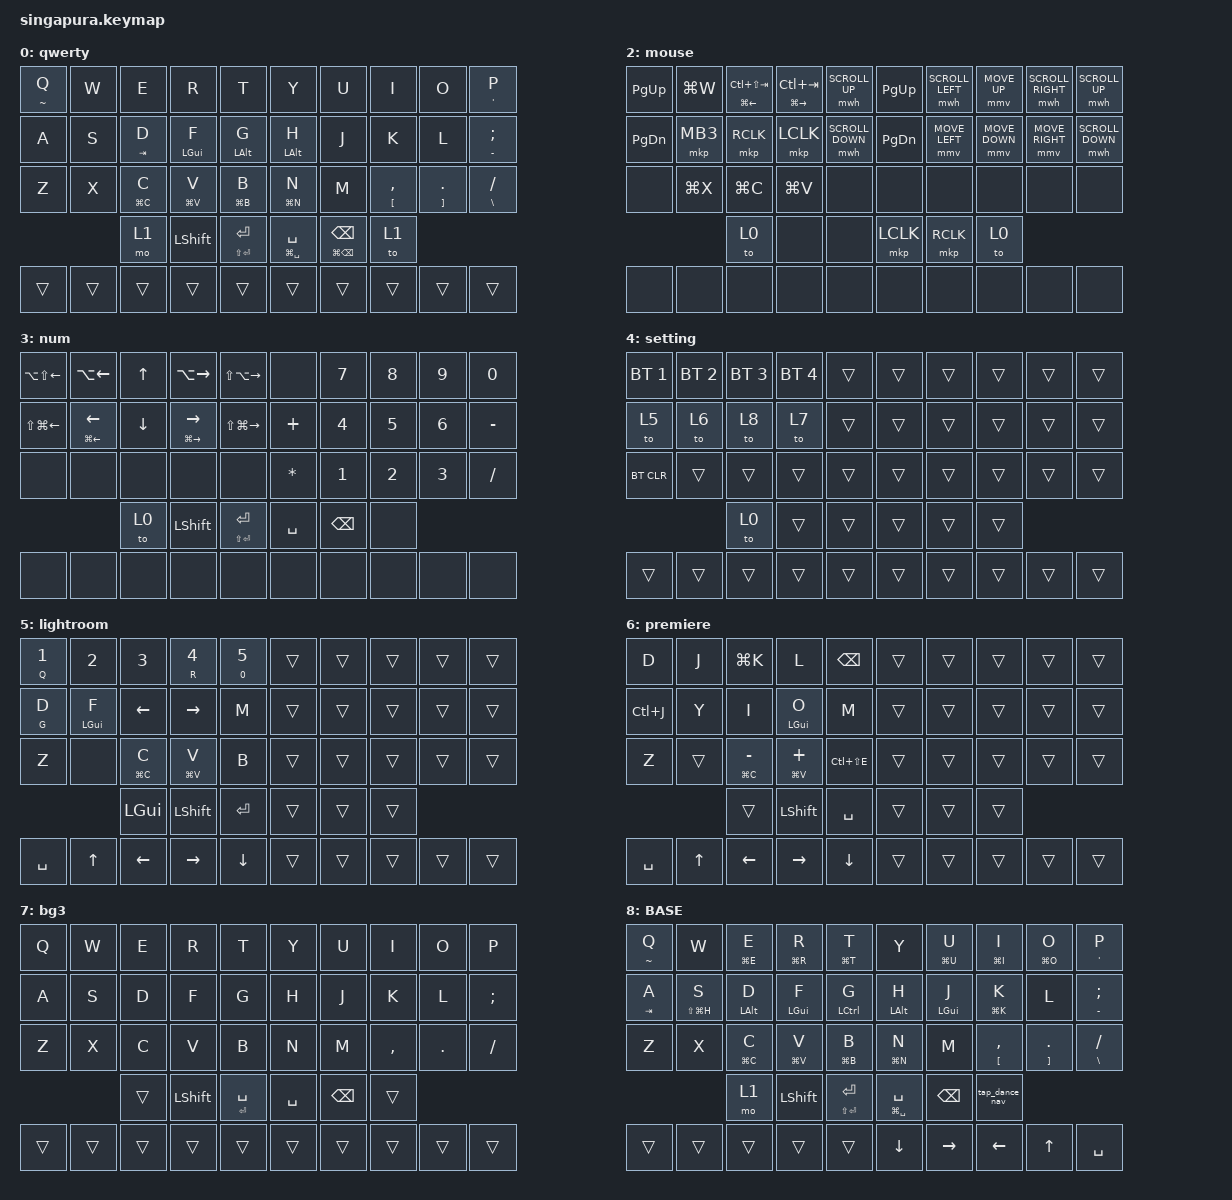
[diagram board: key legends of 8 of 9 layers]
// Copyright 2023 saikocat (@saikocat)
// SPDX-License-Identifier: MIT

#include <behaviors.dtsi>
#include <dt-bindings/zmk/bt.h>
#include <dt-bindings/zmk/keys.h>
#include <dt-bindings/zmk/mouse.h>

#define U_MOUSE_MOVE_MAX 1400

#undef MOVE_UP
#undef MOVE_DOWN
#undef MOVE_LEFT
#undef MOVE_RIGHT

#define MOVE_UP MOVE_VERT(-U_MOUSE_MOVE_MAX)
#define MOVE_DOWN MOVE_VERT(U_MOUSE_MOVE_MAX)
#define MOVE_LEFT MOVE_HOR(-U_MOUSE_MOVE_MAX)
#define MOVE_RIGHT MOVE_HOR(U_MOUSE_MOVE_MAX)
#define U_MOUSE_SCROLL_MAX 12

#undef SCROLL_UP
#undef SCROLL_DOWN
#undef SCROLL_LEFT
#undef SCROLL_RIGHT

#define SCROLL_UP SCROLL_VERT(U_MOUSE_SCROLL_MAX)
#define SCROLL_DOWN SCROLL_VERT(-U_MOUSE_SCROLL_MAX)
#define SCROLL_LEFT SCROLL_HOR(-U_MOUSE_SCROLL_MAX)
#define SCROLL_RIGHT SCROLL_HOR(U_MOUSE_SCROLL_MAX)

&mmv {
    time-to-max-speed-ms = <250>;
    acceleration-exponent = <1>;
};

&mwh {
    time-to-max-speed-ms = <250>;
    acceleration-exponent = <1>;
};

/ {
    combos {
        compatible = "zmk,combos";

        combo_esc {
            timeout-ms = <25>;
            key-positions = <0 1>;
            bindings = <&kp ESC>;
        };

        combo_settings {
            timeout-ms = <25>;
            bindings = <&to 4>;
            key-positions = <31 32 24>;
        };

        combo_pp {
            timeout-ms = <25>;
            bindings = <&kp C_PP>;
            key-positions = <4 5>;
        };

        combo_LEFT_PARENTHESIS {
            timeout-ms = <25>;
            bindings = <&kp LEFT_PARENTHESIS>;
            key-positions = <6 7>;
        };

        combo_RIGHT_PARENTHESIS {
            timeout-ms = <25>;
            bindings = <&kp RIGHT_PARENTHESIS>;
            key-positions = <7 8>;
        };

        combo_VOLUME_UP {
            timeout-ms = <25>;
            bindings = <&kp C_VOLUME_UP>;
            key-positions = <22 23>;
        };

        combo_VOLUME_DOWN {
            timeout-ms = <25>;
            bindings = <&kp C_VOLUME_DOWN>;
            key-positions = <21 20>;
        };

        combo_MUTE {
            timeout-ms = <25>;
            bindings = <&kp C_MUTE>;
            key-positions = <21 22>;
        };

        combo_plus {
            timeout-ms = <25>;
            bindings = <&kp KP_PLUS>;
            key-positions = <19 29>;
        };

        combo_multiply {
            timeout-ms = <25>;
            bindings = <&kp ASTERISK>;
            key-positions = <28 19>;
        };

        combo_equal {
            timeout-ms = <25>;
            bindings = <&kp EQUAL>;
            key-positions = <28 29>;
        };

        combo_no1 {
            timeout-ms = <35>;
            bindings = <&kp N1>;
            key-positions = <34 26>;
        };

        combo_no2 {
            timeout-ms = <35>;
            bindings = <&kp N2>;
            key-positions = <34 27>;
        };

        combo_no3 {
            timeout-ms = <35>;
            bindings = <&kp N3>;
            key-positions = <34 28>;
        };

        combo_no4 {
            timeout-ms = <35>;
            bindings = <&kp N4>;
            key-positions = <34 16>;
        };

        combo_no5 {
            timeout-ms = <35>;
            bindings = <&kp N5>;
            key-positions = <34 17>;
        };

        combo_no6 {
            timeout-ms = <35>;
            bindings = <&kp N6>;
            key-positions = <34 18>;
        };

        combo_no7 {
            timeout-ms = <35>;
            bindings = <&kp N7>;
            key-positions = <34 6>;
        };

        combo_no8 {
            timeout-ms = <35>;
            bindings = <&kp N8>;
            key-positions = <34 7>;
        };

        combo_no9 {
            timeout-ms = <35>;
            bindings = <&kp N9>;
            key-positions = <34 8>;
        };

        combo_no0 {
            timeout-ms = <35>;
            bindings = <&kp N0>;
            key-positions = <9 34>;
        };

        combo_leftscreen {
            timeout-ms = <25>;
            bindings = <&kp F7>;
            key-positions = <0 10>;
        };

        combo_rightscreen {
            timeout-ms = <25>;
            bindings = <&kp F9>;
            key-positions = <4 14>;
        };

        combo_nexttrack {
            timeout-ms = <25>;
            bindings = <&kp C_NEXT>;
            key-positions = <21 22 23>;
        };

        combo_prevtrack {
            timeout-ms = <25>;
            bindings = <&kp C_PREV>;
            key-positions = <20 21 22>;
        };

        combo_changelang {
            timeout-ms = <35>;
            bindings = <&kp LC(SPACE)>;
            key-positions = <14 13 15 16>;
        };

        combo_spaces {
            timeout-ms = <30>;
            bindings = <&kp F8>;
            key-positions = <1 3>;
        };

        combo_to0 {
            timeout-ms = <15>;
            bindings = <&to 0>;
            key-positions = <31 32>;
        };

        combo_screenshot {
            timeout-ms = <35>;
            bindings = <&kp LG(LS(N4))>;
            key-positions = <0 20 9 29>;
        };

        combo_minus {
            timeout-ms = <25>;
            bindings = <&kp MINUS>;
            key-positions = <18 19>;
        };

        combo_macro_skmr {
            bindings = <&macro_skmr>;
            key-positions = <34 26 31 23>;
        };

        combo_homerow_scroll {
            bindings = <&kp LA(LC(LG(W)))>;
            key-positions = <19 34>;
        };

        combo_homerow_search {
            timeout-ms = <25>;
            bindings = <&kp LA(LC(LG(Q)))>;
            key-positions = <35 30>;
        };

        combo_moom_toggle {
            timeout-ms = <25>;
            bindings = <&kp LA(LC(LG(E)))>;
            key-positions = <1 2>;
        };
    };

    behaviors {
        gqt: global-quick-tap {
            compatible = "zmk,behavior-hold-tap";
            label = "GLOBAL_QUICK_TAP";
            #binding-cells = <2>;
            flavor = "tap-preferred";
            tapping-term-ms = <200>;
            quick-tap-ms = <120>;
            global-quick-tap;
            bindings = <&kp>, <&kp>;
        };

        tap_dance_nav: tap_dance_nav {
            compatible = "zmk,behavior-tap-dance";
            label = "TAP_DANCE_NAV";
            #binding-cells = <0>;
            tapping-term-ms = <200>;
            bindings = <&to 1>, <&to 2>, <&to 3>;
        };
    };

    macros {
        macro_skmr: macro_skmr {
            compatible = "zmk,behavior-macro";
            label = "MACRO_SKMR";
            #binding-cells = <0>;
            bindings = <&none &kp LS(I) &kp SPACE &kp F &kp E &kp E &kp L &kp SPACE &kp L &kp I &kp K &kp E &kp SPACE &kp W &kp E &kp SPACE &kp H &kp A &kp V &kp E &kp SPACE &kp G &kp O &kp N &kp E &kp SPACE &kp P &kp A &kp S &kp T &kp SPACE &kp S &kp O &kp C &kp I &kp A &kp L &kp SPACE &kp N &kp O &kp R &kp M &kp S &kp SPACE &kp H &kp A &kp H &kp H &kp A &kp A &kp H &kp A &kp H &kp H &kp H>;
        };

        marco_task_switcher: task_switcher {
            compatible = "zmk,behavior-macro";
            #binding-cells = <0>;
            bindings = <&kp LG(TAB) &sk LEFT_GUI>;
            label = "TASK_SWITCHER";
        };
    };

    keymap {
        compatible = "zmk,keymap";

        qwerty {
            bindings = <
&gqt TILDE Q  &kp W   &kp E         &kp R            &kp T                 &kp Y                 &kp U                         &kp I                    &kp O                   &gqt SINGLE_QUOTE P
&kp A         &kp S   &gqt TAB D    &gqt LEFT_GUI F  &gqt LEFT_ALT G       &gqt LEFT_ALT H       &kp J                         &kp K                    &kp L                   &gqt MINUS SEMI
&kp Z         &kp X   &gqt LG(C) C  &gqt LG(V) V     &gqt LG(B) B          &gqt LG(N) N          &kp M                         &gqt LEFT_BRACKET COMMA  &gqt RIGHT_BRACKET DOT  &gqt BACKSLASH SLASH
                      &mo 1         &kp LSHIFT       &gqt LS(ENTER) ENTER  &gqt LG(SPACE) SPACE  &gqt LG(BACKSPACE) BACKSPACE  &to 1
&trans        &trans  &trans        &trans           &trans                &trans                &trans                        &trans                   &trans                  &trans
            >;
        };

        nav {
            bindings = <
&kp PAGE_UP    &kp LG(TAB)     &gqt LG(LEFT) LS(LC(TAB))  &gqt LG(RIGHT) LC(TAB)  &kp LG(Z)             &kp LS(LA(LEFT))  &kp LA(LEFT)        &kp UP_ARROW       &kp LA(RIGHT)         &kp LS(LA(RIGHT))
&kp PAGE_DOWN  &kp LEFT_SHIFT  &sk LEFT_ALT               &sk LEFT_GUI            &sk LCTRL             &kp LS(LG(LEFT))  &gqt LG(LEFT) LEFT  &kp DOWN_ARROW     &gqt LG(RIGHT) RIGHT  &kp LS(LG(RIGHT))
&to 2          &kp LG(X)       &kp LG(C)                  &kp LG(V)               &kp LG(LS(Z))         &none             &none               &none              &none                 &kp LA(LG(LC(R)))
                               &to 0                      &kp LEFT_SHIFT          &gqt LS(ENTER) ENTER  &kp SPACE         &kp BACKSPACE       &kp LA(LG(LC(Q)))
&none          &none           &none                      &none                   &none                 &none             &none               &none              &none                 &none
            >;
        };

        mouse {
            bindings = <
&kp PAGE_UP    &kp LG(W)  &gqt LG(LEFT) LC(LS(TAB))  &gqt LG(RIGHT) LC(TAB)  &mwh SCROLL_UP    &kp PAGE_UP    &mwh SCROLL_LEFT  &mmv MOVE_UP    &mwh SCROLL_RIGHT  &mwh SCROLL_UP
&kp PAGE_DOWN  &mkp MB3   &mkp RCLK                  &mkp LCLK               &mwh SCROLL_DOWN  &kp PAGE_DOWN  &mmv MOVE_LEFT    &mmv MOVE_DOWN  &mmv MOVE_RIGHT    &mwh SCROLL_DOWN
&none          &kp LG(X)  &kp LG(C)                  &kp LG(V)               &none             &none          &none             &none           &none              &none
                          &to 0                      &none                   &none             &mkp LCLK      &mkp RCLK         &to 0
&none          &none      &none                      &none                   &none             &none          &none             &none           &none              &none
            >;
        };

        num {
            bindings = <
&kp LA(LS(LEFT_ARROW))  &kp LA(LEFT)        &kp UP_ARROW  &kp LA(RIGHT)         &kp LS(LA(RIGHT))     &none         &kp N7         &kp N8        &kp N9        &kp N0
&kp LS(LG(LEFT))        &gqt LG(LEFT) LEFT  &kp DOWN      &gqt LG(RIGHT) RIGHT  &kp LS(LG(RIGHT))     &kp PLUS      &kp NUMBER_4   &kp N5        &kp NUMBER_6  &kp MINUS
&none                   &none               &none         &none                 &none                 &kp ASTERISK  &kp NUMBER_1   &kp NUMBER_2  &kp NUMBER_3  &kp SLASH
                                            &to 0         &kp LEFT_SHIFT        &gqt LS(ENTER) ENTER  &kp SPACE     &kp BACKSPACE  &none
&none                   &none               &none         &none                 &none                 &none         &none          &none         &none         &none
            >;
        };

        setting {
            bindings = <
&bt BT_SEL 1  &bt BT_SEL 2  &bt BT_SEL 3  &bt BT_SEL 4  &trans  &trans  &trans  &trans  &trans  &trans
&to 5         &to 6         &to 8         &to 7         &trans  &trans  &trans  &trans  &trans  &trans
&bt BT_CLR    &trans        &trans        &trans        &trans  &trans  &trans  &trans  &trans  &trans
                            &to 0         &trans        &trans  &trans  &trans  &trans
&trans        &trans        &trans        &trans        &trans  &trans  &trans  &trans  &trans  &trans
            >;
        };

        lightroom {
            bindings = <
&gqt Q NUMBER_1  &kp NUMBER_2     &kp NUMBER_3  &gqt R NUMBER_4  &gqt NUMBER_0 NUMBER_5  &trans  &trans  &trans  &trans  &trans
&gqt G D         &gqt LEFT_GUI F  &kp LEFT      &kp RIGHT        &kp M                   &trans  &trans  &trans  &trans  &trans
&kp Z            &none            &gqt LG(C) C  &gqt LG(V) V     &kp B                   &trans  &trans  &trans  &trans  &trans
                                  &kp LEFT_GUI  &kp LEFT_SHIFT   &kp ENTER               &trans  &trans  &trans
&kp SPACE        &kp UP_ARROW     &kp LEFT      &kp RIGHT        &kp DOWN                &trans  &trans  &trans  &trans  &trans
            >;
        };

        premiere {
            bindings = <
&kp D      &kp J         &kp LG(K)         &kp L            &kp BACKSPACE  &trans  &trans  &trans  &trans  &trans
&kp LC(J)  &kp Y         &kp I             &gqt LEFT_GUI O  &kp M          &trans  &trans  &trans  &trans  &trans
&kp Z      &trans        &gqt LG(C) MINUS  &gqt LG(V) PLUS  &kp LC(LS(E))  &trans  &trans  &trans  &trans  &trans
                         &trans            &kp LEFT_SHIFT   &kp SPACE      &trans  &trans  &trans
&kp SPACE  &kp UP_ARROW  &kp LEFT          &kp RIGHT        &kp DOWN       &trans  &trans  &trans  &trans  &trans
            >;
        };

        bg3 {
            bindings = <
&kp Q   &kp W   &kp E   &kp R       &kp T             &kp Y      &kp U          &kp I      &kp O    &kp P
&kp A   &kp S   &kp D   &kp F       &kp G             &kp H      &kp J          &kp K      &kp L    &kp SEMI
&kp Z   &kp X   &kp C   &kp V       &kp B             &kp N      &kp M          &kp COMMA  &kp DOT  &kp FSLH
                &trans  &kp LSHIFT  &gqt ENTER SPACE  &kp SPACE  &kp BACKSPACE  &trans
&trans  &trans  &trans  &trans      &trans            &trans     &trans         &trans     &trans   &trans
            >;
        };

        base {
            label = "BASE";
            bindings = <
&gqt TILDE Q  &kp W             &gqt LG(E) E  &gqt LG(R) R    &gqt LG(T) T          &kp Y                 &gqt LG(U) U   &gqt LG(I) I             &gqt LG(O) O               &gqt SINGLE_QUOTE P
&gqt TAB A    &gqt LS(LG(H)) S  &gqt LALT D   &gqt LGUI F     &gqt LCTRL G          &gqt LALT H           &gqt LGUI J    &gqt LG(K) K             &kp L                      &gqt MINUS SEMICOLON
&kp Z         &kp X             &gqt LG(C) C  &gqt LG(V) V    &gqt LG(B) B          &gqt LG(N) N          &kp M          &gqt LEFT_BRACKET COMMA  &gqt RIGHT_BRACKET PERIOD  &gqt BSLH FSLH
                                &mo 1         &kp LEFT_SHIFT  &gqt LS(ENTER) ENTER  &gqt LG(SPACE) SPACE  &kp BACKSPACE  &tap_dance_nav
&trans        &trans            &trans        &trans          &trans                &kp DOWN              &kp RIGHT      &kp LEFT                 &kp UP                     &kp SPACE
            >;
        };
    };
};

// vim: ft=dts et
